# MAX32550 register map
Vendor: Maxim Integrated; File version: 1.0
Registers are 32-bit, read-write, reset 0x0 unless marked. A register's access mark holds for its fields unless they carry their own. Offsets are from the block's base; [hi:lo] are bit positions; 'fields as' and 'values as' point back to an identical list.

## MonoLCDController — LCD Interface
Base 0x40030000; register names take the prefix LCD_
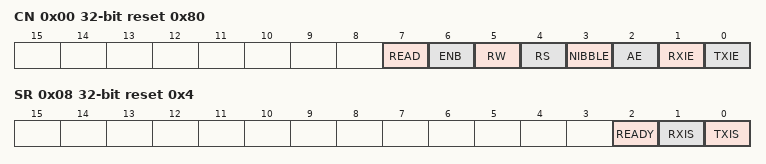
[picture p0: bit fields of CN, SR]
0x00 CN reset 0x80 — LCD Control Register
  [7] READ
    0=complete (No operation/complete); 1=Start operation
  [6] ENB — Enable (Active Low). In Automatic Mode, this bit sets the polarity of the LCD_EN pin. (0: LCD_EN is active high. 1: LCD_EN is active low.) In Manual Mode, this bit directly sets the LCD_EN pin state.
    0=loOrActiveHi (If automatic mode, LCD_EN is active high, else LCD is set low.); 1=hiOrActiveLo (If automatic mode, LCD_EN is active low, else LCD is set high.)
  [5] RW — Register Select. This bit sets the logic level of the LCD_RS pin.
    0=lo (Logic 0 (low)); 1=hi (Logic 1 (high))
  [4] RS — Register Select. This bit sets the logic level of the LCD_RS pin.
    0=lo (Logic 0 (low)); 1=hi (Logic 1 (high))
  [3] NIBBLE — Bus Width Select
    0=width8bit (8 bit bus width); 1=width4bit (4 bit bus width (This feature is only available when AUTOEN=1))
  [2] AE — Automatic Mode Enable
    0=disable; 1=enable
  [1] RXIE — Data Receive Interrupt Enable
    0=disable; 1=enable
  [0] TXIE — Data Transmit Interrupt Enable
    0=disable; 1=enable
0x04 EPR 8-bit reset 0x18 — LCD Enable Period Register. This register specifies the number of system clock cycles for an access. It is twice the asserted time of the enable signal (LCD_EN pin). This register has a minimum value of 4. Any value less than 4 will be set to 4.
0x08 SR reset 0x4 — LCD Status Register
  [2] READY ro — LCD Ready
    0=busy; 1=ready
  [1] RXIS — Receive Status
    0=noDataAvailable (No data has been received.); 1=dataAvailable (Data is available in LCD_DATA register. This bit is set by hardware and must be cleared by software to be acknowledged.)
  [0] TXIS — Transmission Status
    0=notSent (The content of the data register has not yet been sent.); 1=sent (The content of the data register has been sent. This bit is set by hardware and must be cleared by software to be acknowledged.)
0x0C DATA 8-bit — Data register for LCD read/write operation

## RealTimeClock — Real Time Clock and Alarm
Base 0x40006000; register names take the prefix RTC_
0x00 SEC reset not defined — RTC Second Counter. This register contains the 32-bit second counter.
0x04 SSEC 8-bit reset not defined — RTC Sub-second Counter. This counter increments at 256Hz. RTC_SEC is incremented when this register rolls over from 0xFF to 0x00.
0x08 RAS 20-bit reset not defined — Time-of-day Alarm
0x0C RSSA 8-bit reset not defined — RTC sub-second alarm. This register contains the reload value for the sub-second alarm.
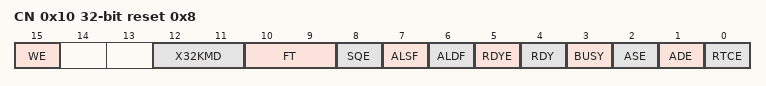
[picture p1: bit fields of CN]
0x10 CN reset 0x8 (reset mask 0xFFFFFF38) — RTC Control Register
  [15] WE — Write Enable. This register bit serves as a protection mechanism against unintentional writes to critical RTC bits.
    0=disable; 1=enable
  [12:11] X32KMD — 32KHz Oscillator Mode.
    0=noiseImmuneMode (Always operate in Noise Immune Mode. Oscillator warm-up required.); 1=quietMode (Always operate in Quiet Mode. No oscillator warm-up required.); 2=quietInStopWithWarmup (Operate in Noise Immune Mode normally, switch to Quiet Mode on Stop Mode entry. Will wait for 32K oscillator warm-up before code execution on Stop Mode exit.); 3=quietInStopNoWarmup (Operate in Noise Immune Mode normally, switch to Quiet Mode on Stop Mode entry. Will not wait for 32K oscillator warm-up before code execution on Stop Mode exit.)
  [10:9] FT — Frequency Output Selection. When SQE=1, these bits specify the output frequency on the SQW pin.
    0=freq1Hz (1 Hz (Compensated)); 1=freq512Hz (512 Hz (Compensated)); other=RTC Input Clock
  [8] SQE — Square Wave Output Enable
    0=disable; 1=enable
  [7] ALSF ro — Sub-second Alarm Interrupt Flag. This alarm is qualified as wake-up source to the processor.
    0=inactive (No interrupt is pending.); 1=pending (An interrupt is pending.)
  [6] ALDF ro — Time-of-Day Alarm Interrupt Flag. This alarm is qualified as wake-up source to the processor.
    values as ALSF
  [5] RDYE — RTC Ready Interrupt Enable
    0=disable; 1=enable
  [4] RDY — RTC Ready. This bit is set to 1 by hardware when the RTC count registers update. It can be cleared to 0 by software at any time. It will also be cleared to 0 by hardware just prior to an update of the RTC count register.
    0=busy; 1=ready
  [3] BUSY ro — RTC Busy. This bit is set to 1 by hardware when changes to RTC registers required a synchronized version of the register to be in place. This bit is automatically cleared by hardware.
    0=idle; 1=busy
  [2] ASE — Alarm Sub-second Interrupt Enable. Change to this bit is effective only after BUSY is cleared from 1 to 0.
    0=disable; 1=enable
  [1] ADE — Alarm Time-of-Day Interrupt Enable. Change to this bit is effective only after BUSY is cleared from 1 to 0.
    0=disable; 1=enable
  [0] RTCE — Real Time Clock Enable. This bit enables the Real Time Clock. This bit can only be written when WE=1 and BUSY =0. Change to this bit is effective only after BUSY is cleared from 1 to 0.
    0=disable; 1=enable
0x14 TRIM 8-bit reset not defined — RTC Trim. This register contains the 2's complement value that specifies the trim resolution. Each increment or decrement of the bit adds or subtracts 1ppm at each 4KHz clock value, with a maximum correction of +/- 127ppm.
